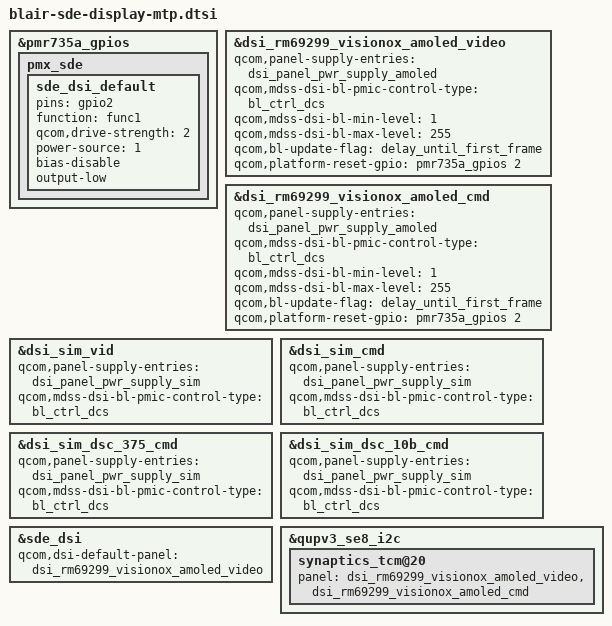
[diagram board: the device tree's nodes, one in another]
#include "blair-sde-display.dtsi"

&pmr735a_gpios {
	pmx_sde: pmx_sde {
		sde_dsi_default: sde_dsi_default {
			pins = "gpio2";
			function = "func1";
			qcom,drive-strength = <2>;
			power-source = <1>;
			bias-disable;
			output-low;
		};
	};
};

&dsi_rm69299_visionox_amoled_video {
	qcom,panel-supply-entries = <&dsi_panel_pwr_supply_amoled>;
	qcom,mdss-dsi-bl-pmic-control-type = "bl_ctrl_dcs";
	qcom,mdss-dsi-bl-min-level = <1>;
	qcom,mdss-dsi-bl-max-level = <255>;
	qcom,bl-update-flag = "delay_until_first_frame";
	qcom,platform-reset-gpio = <&pmr735a_gpios 2 0>;
};

&dsi_rm69299_visionox_amoled_cmd {
	qcom,panel-supply-entries = <&dsi_panel_pwr_supply_amoled>;
	qcom,mdss-dsi-bl-pmic-control-type = "bl_ctrl_dcs";
	qcom,mdss-dsi-bl-min-level = <1>;
	qcom,mdss-dsi-bl-max-level = <255>;
	qcom,bl-update-flag = "delay_until_first_frame";
	qcom,platform-reset-gpio = <&pmr735a_gpios 2 0>;
};

&dsi_sim_vid {
	qcom,panel-supply-entries = <&dsi_panel_pwr_supply_sim>;
	qcom,mdss-dsi-bl-pmic-control-type = "bl_ctrl_dcs";
};

&dsi_sim_cmd {
	qcom,panel-supply-entries = <&dsi_panel_pwr_supply_sim>;
	qcom,mdss-dsi-bl-pmic-control-type = "bl_ctrl_dcs";
};

&dsi_sim_dsc_375_cmd {
	qcom,panel-supply-entries = <&dsi_panel_pwr_supply_sim>;
	qcom,mdss-dsi-bl-pmic-control-type = "bl_ctrl_dcs";
};

&dsi_sim_dsc_10b_cmd {
	qcom,panel-supply-entries = <&dsi_panel_pwr_supply_sim>;
	qcom,mdss-dsi-bl-pmic-control-type = "bl_ctrl_dcs";
};

&sde_dsi {
	qcom,dsi-default-panel = <&dsi_rm69299_visionox_amoled_video>;
};

&qupv3_se8_i2c {
	synaptics_tcm@20 {
		panel = <&dsi_rm69299_visionox_amoled_video
			&dsi_rm69299_visionox_amoled_cmd>;
	};
};
